# EFM32G222F128 register map
File version: 5.2.1
Registers are 32-bit, read-write, reset 0x0 unless marked. A register's access mark holds for its fields unless they carry their own. Offsets are from the block's base; [hi:lo] are bit positions; {n}, {i} and the like mark numbered series.

## ACMP0
Base 0x40001000
Same registers: ACMP1 0x40001400
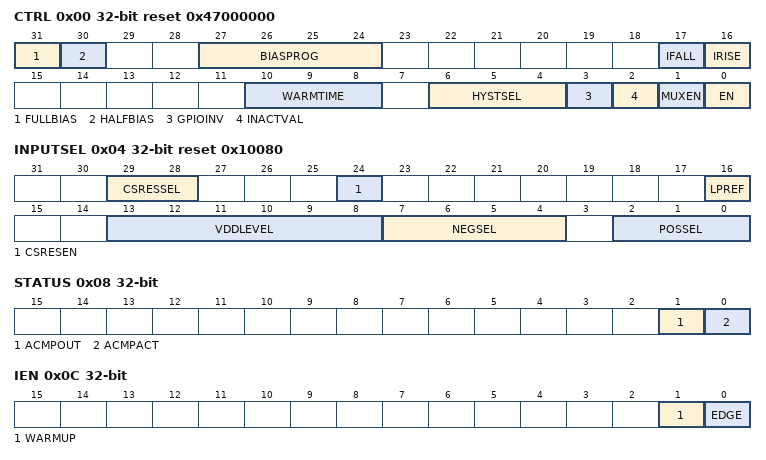
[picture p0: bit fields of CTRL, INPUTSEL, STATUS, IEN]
0x00 CTRL reset 0x47000000 — Control Register
  [31] FULLBIAS — Full Bias Current
  [30] HALFBIAS — Half Bias Current
  [27:24] BIASPROG — Bias Configuration
  [17] IFALL — Falling Edge Interrupt Sense
  [16] IRISE — Rising Edge Interrupt Sense
  [10:8] WARMTIME — Warm-up Time
    0=4CYCLES (4 HFPERCLK cycles.); 1=8CYCLES (8 HFPERCLK cycles.); 2=16CYCLES (16 HFPERCLK cycles.); 3=32CYCLES (32 HFPERCLK cycles.); 4=64CYCLES (64 HFPERCLK cycles.); 5=128CYCLES (128 HFPERCLK cycles.); 6=256CYCLES (256 HFPERCLK cycles.); 7=512CYCLES (512 HFPERCLK cycles.)
  [6:4] HYSTSEL — Hysteresis Select
    0=HYST0 (No hysteresis.); 1=HYST1 (~15 mV hysteresis.); 2=HYST2 (~22 mV hysteresis.); 3=HYST3 (~29 mV hysteresis.); 4=HYST4 (~36 mV hysteresis.); 5=HYST5 (~43 mV hysteresis.); 6=HYST6 (~50 mV hysteresis.); 7=HYST7 (~57 mV hysteresis.)
  [3] GPIOINV — Comparator GPIO Output Invert
  [2] INACTVAL — Inactive Value
  [1] MUXEN — Input Mux Enable
  [0] EN — Analog Comparator Enable
0x04 INPUTSEL reset 0x10080 — Input Selection Register
  [29:28] CSRESSEL — Capacitive Sense Mode Internal Resistor Select
    {v}=RES{v} (Internal capacitive sense resistor value {v}.) (v=0..3)
  [24] CSRESEN — Capacitive Sense Mode Internal Resistor Enable
  [16] LPREF — Low Power Reference Mode
  [13:8] VDDLEVEL — VDD Reference Level
  [7:4] NEGSEL — Negative Input Select
    {v}=CH{v} (Channel {v} as negative input.) (v=0..7); 8=1V25 (1.25 V as negative input.); 9=2V5 (2.5 V as negative input.); 10=VDD (Scaled VDD as negative input.); 11=CAPSENSE (Capacitive sense mode.)
  [2:0] POSSEL — Positive Input Select
    {v}=CH{v} (Channel {v} as positive input.) (v=0..7)
0x08 STATUS ro
  [1] ACMPOUT — Analog Comparator Output
  [0] ACMPACT — Analog Comparator Active
0x0C IEN — Interrupt Enable Register
  [1] WARMUP — Warm-up Interrupt Enable
  [0] EDGE — Edge Trigger Interrupt Enable
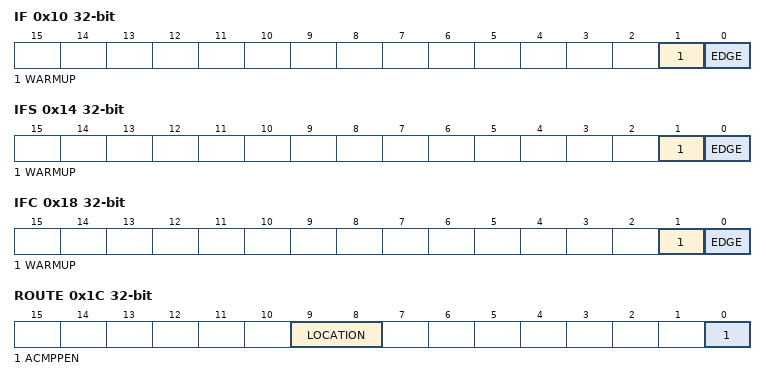
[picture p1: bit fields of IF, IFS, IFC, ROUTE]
0x10 IF ro — Interrupt Flag Register
  [1] WARMUP — Warm-up Interrupt Flag
  [0] EDGE — Edge Triggered Interrupt Flag
0x14 IFS wo — Interrupt Flag Set Register
  [1] WARMUP — Warm-up Interrupt Flag Set
  [0] EDGE — Edge Triggered Interrupt Flag Set
0x18 IFC wo — Interrupt Flag Clear Register
  [1] WARMUP — Warm-up Interrupt Flag Clear
  [0] EDGE — Edge Triggered Interrupt Flag Clear
0x1C ROUTE — I/O Routing Register
  [9:8] LOCATION — I/O Location
    0=LOC0 (Location 0); 1=LOC1 (Location 1)
  [0] ACMPPEN — ACMP Output Pin Enable

## PRS
Base 0x400CC000
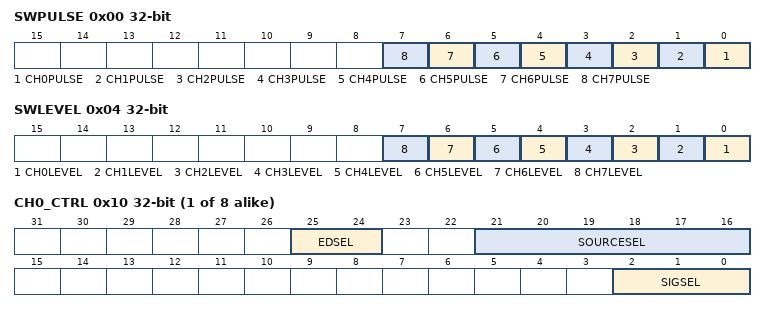
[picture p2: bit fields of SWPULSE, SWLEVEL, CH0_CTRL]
0x00 SWPULSE wo — Software Pulse Register
  [n] CH{n}PULSE (n=0..7) — Channel {n} Pulse Generation
0x04 SWLEVEL — Software Level Register
  [n] CH{n}LEVEL (n=0..7) — Channel {n} Software Level
{0x10+4i} CH{i}_CTRL (i=0..7) — Channel Control Register
  [25:24] EDSEL — Edge Detect Select
    0=OFF (Signal is left as it is); 1=POSEDGE (A one HFPERCLK cycle pulse is generated for every positive edge of the incoming signal); 2=NEGEDGE (A one HFPERCLK clock cycle pulse is generated for every negative edge of the incoming signal); 3=BOTHEDGES (A one HFPERCLK clock cycle pulse is generated for every edge of the incoming signal)
  [21:16] SOURCESEL — Source Select
    0=NONE (No source selected); 1=VCMP (Voltage Comparator); 2=ACMP0 (Analog Comparator 0); 3=ACMP1 (Analog Comparator 1); 6=DAC0 (Digital to Analog Converter 0); 8=ADC0 (Analog to Digital Converter 0); 16=USART0 (Universal Synchronous/Asynchronous Receiver/Transmitter 0); 17=USART1 (Universal Synchronous/Asynchronous Receiver/Transmitter 1); 28=TIMER0; 29=TIMER1; 30=TIMER2; 40=RTC (Real-Time Counter); 48=GPIOL (General purpose Input/Output); 49=GPIOH (General purpose Input/Output)
  [2:0] SIGSEL — Signal Select

## DAC0
Base 0x40004000
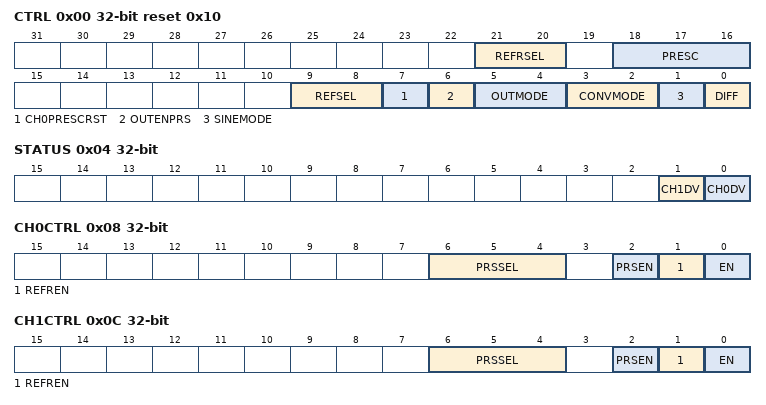
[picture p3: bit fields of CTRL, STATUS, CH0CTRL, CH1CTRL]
0x00 CTRL reset 0x10 — Control Register
  [21:20] REFRSEL — Refresh Interval Select
    0=8CYCLES (All channels with enabled refresh are refreshed every 8 prescaled cycles); 1=16CYCLES (All channels with enabled refresh are refreshed every 16 prescaled cycles); 2=32CYCLES (All channels with enabled refresh are refreshed every 32 prescaled cycles); 3=64CYCLES (All channels with enabled refresh are refreshed every 64 prescaled cycles)
  [18:16] PRESC — Prescaler Setting
    0=NODIVISION
  [9:8] REFSEL — Reference Selection
    0=1V25 (Internal 1.25 V bandgap reference); 1=2V5 (Internal 2.5 V bandgap reference); 2=VDD (VDD reference)
  [7] CH0PRESCRST — Channel 0 Start Reset Prescaler
  [6] OUTENPRS — PRS Controlled Output Enable
  [5:4] OUTMODE — Output Mode
    0=DISABLE (DAC output to pin and ADC disabled); 1=PIN (DAC output to pin enabled. DAC output to ADC disabled); 2=ADC (DAC output to pin disabled. DAC output to ADC enabled); 3=PINADC (DAC output to pin and ADC enabled)
  [3:2] CONVMODE — Conversion Mode
    0=CONTINUOUS (DAC is set in continuous mode); 1=SAMPLEHOLD (DAC is set in sample/hold mode); 2=SAMPLEOFF (DAC is set in sample/shut off mode)
  [1] SINEMODE
  [0] DIFF — Differential Mode
0x04 STATUS ro
  [1] CH1DV — Channel 1 Data Valid
  [0] CH0DV — Channel 0 Data Valid
0x08 CH0CTRL — Channel 0 Control Register
  [6:4] PRSSEL — Channel 0 PRS Trigger Select
    {v}=PRSCH{v} (PRS ch {v} triggers channel 0 conversion.) (v=0..7)
  [2] PRSEN — Channel 0 PRS Trigger Enable
  [1] REFREN — Channel 0 Automatic Refresh Enable
  [0] EN — Channel 0 Enable
0x0C CH1CTRL — Channel 1 Control Register
  [6:4] PRSSEL — Channel 1 PRS Trigger Select
    {v}=PRSCH{v} (PRS ch {v} triggers channel 1 conversion.) (v=0..7)
  [2] PRSEN — Channel 1 PRS Trigger Enable
  [1] REFREN — Channel 1 Automatic Refresh Enable
  [0] EN — Channel 1 Enable
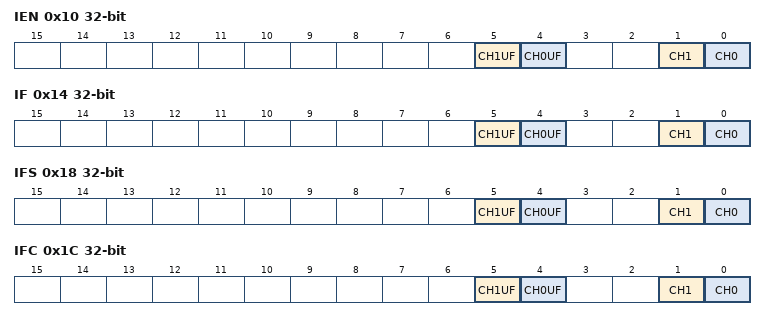
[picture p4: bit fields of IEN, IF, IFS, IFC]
0x10 IEN — Interrupt Enable Register
  [5] CH1UF — Channel 1 Conversion Data Underflow Interrupt Enable
  [4] CH0UF — Channel 0 Conversion Data Underflow Interrupt Enable
  [1] CH1 — Channel 1 Conversion Complete Interrupt Enable
  [0] CH0 — Channel 0 Conversion Complete Interrupt Enable
0x14 IF ro — Interrupt Flag Register
  [5] CH1UF — Channel 1 Data Underflow Interrupt Flag
  [4] CH0UF — Channel 0 Data Underflow Interrupt Flag
  [1] CH1 — Channel 1 Conversion Complete Interrupt Flag
  [0] CH0 — Channel 0 Conversion Complete Interrupt Flag
0x18 IFS wo — Interrupt Flag Set Register
  [5] CH1UF — Channel 1 Data Underflow Interrupt Flag Set
  [4] CH0UF — Channel 0 Data Underflow Interrupt Flag Set
  [1] CH1 — Channel 1 Conversion Complete Interrupt Flag Set
  [0] CH0 — Channel 0 Conversion Complete Interrupt Flag Set
0x1C IFC wo — Interrupt Flag Clear Register
  [5] CH1UF — Channel 1 Data Underflow Interrupt Flag Clear
  [4] CH0UF — Channel 0 Data Underflow Interrupt Flag Clear
  [1] CH1 — Channel 1 Conversion Complete Interrupt Flag Clear
  [0] CH0 — Channel 0 Conversion Complete Interrupt Flag Clear
0x20 CH0DATA — Channel 0 Data Register
  [11:0] DATA — Channel 0 Data
0x24 CH1DATA — Channel 1 Data Register
  [11:0] DATA — Channel 1 Data
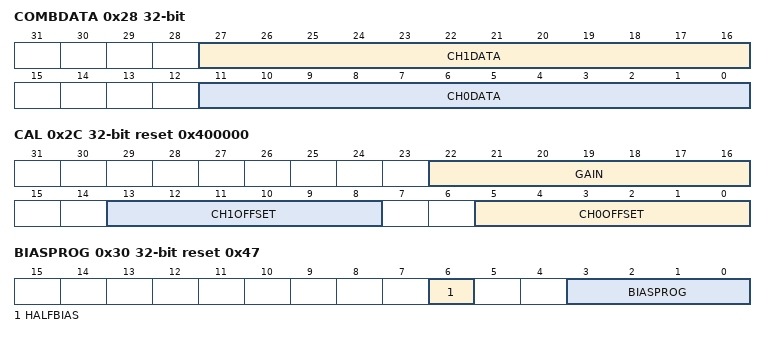
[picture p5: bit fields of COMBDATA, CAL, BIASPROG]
0x28 COMBDATA wo — Combined Data Register
  [27:16] CH1DATA — Channel 1 Data
  [11:0] CH0DATA — Channel 0 Data
0x2C CAL reset 0x400000 — Calibration Register
  [22:16] GAIN — Gain Calibration Value
  [13:8] CH1OFFSET — Channel 1 Offset Calibration Value
  [5:0] CH0OFFSET — Channel 0 Offset Calibration Value
0x30 BIASPROG reset 0x47 — Bias Programming Register
  [6] HALFBIAS — Half Bias Current
  [3:0] BIASPROG — Bias Programming Value

## VCMP
Base 0x40000000
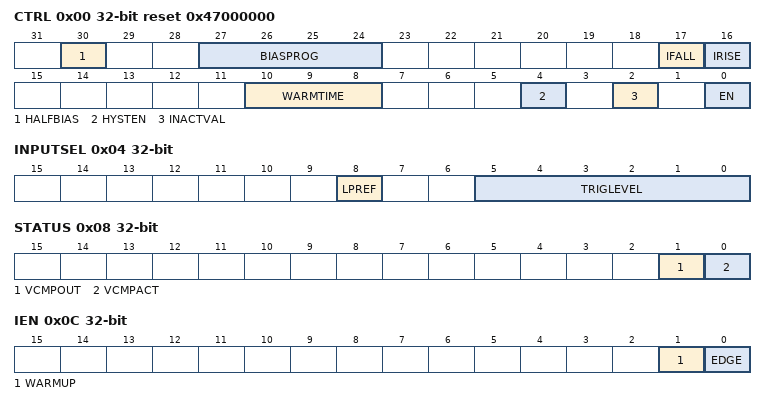
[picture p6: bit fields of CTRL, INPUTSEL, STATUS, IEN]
0x00 CTRL reset 0x47000000 — Control Register
  [30] HALFBIAS — Half Bias Current
  [27:24] BIASPROG — VCMP Bias Programming Value
  [17] IFALL — Falling Edge Interrupt Sense
  [16] IRISE — Rising Edge Interrupt Sense
  [10:8] WARMTIME — Warm-Up Time
    0=4CYCLES (4 HFPERCLK cycles); 1=8CYCLES (8 HFPERCLK cycles); 2=16CYCLES (16 HFPERCLK cycles); 3=32CYCLES (32 HFPERCLK cycles); 4=64CYCLES (64 HFPERCLK cycles); 5=128CYCLES (128 HFPERCLK cycles); 6=256CYCLES (256 HFPERCLK cycles); 7=512CYCLES (512 HFPERCLK cycles)
  [4] HYSTEN — Hysteresis Enable
  [2] INACTVAL — Inactive Value
  [0] EN — Voltage Supply Comparator Enable
0x04 INPUTSEL — Input Selection Register
  [8] LPREF — Low Power Reference
  [5:0] TRIGLEVEL — Trigger Level
0x08 STATUS ro
  [1] VCMPOUT — Voltage Supply Comparator Output
  [0] VCMPACT — Voltage Supply Comparator Active
0x0C IEN — Interrupt Enable Register
  [1] WARMUP — Warm-up Interrupt Enable
  [0] EDGE — Edge Trigger Interrupt Enable
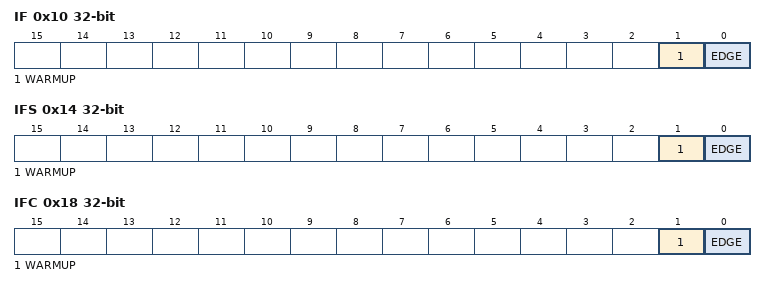
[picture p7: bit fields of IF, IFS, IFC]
0x10 IF ro — Interrupt Flag Register
  [1] WARMUP — Warm-up Interrupt Flag
  [0] EDGE — Edge Triggered Interrupt Flag
0x14 IFS wo — Interrupt Flag Set Register
  [1] WARMUP — Warm-up Interrupt Flag Set
  [0] EDGE — Edge Triggered Interrupt Flag Set
0x18 IFC wo — Interrupt Flag Clear Register
  [1] WARMUP — Warm-up Interrupt Flag Clear
  [0] EDGE — Edge Triggered Interrupt Flag Clear

## WDOG
Base 0x40088000
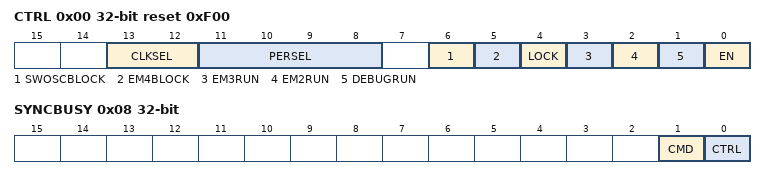
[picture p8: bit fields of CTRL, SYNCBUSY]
0x00 CTRL reset 0xF00 — Control Register
  [13:12] CLKSEL — Watchdog Clock Select
    0=ULFRCO; 1=LFRCO; 2=LFXO
  [11:8] PERSEL — Watchdog Timeout Period Select
  [6] SWOSCBLOCK — Software Oscillator Disable Block
  [5] EM4BLOCK — Energy Mode 4 Block
  [4] LOCK — Configuration lock
  [3] EM3RUN — Energy Mode 3 Run Enable
  [2] EM2RUN — Energy Mode 2 Run Enable
  [1] DEBUGRUN — Debug Mode Run Enable
  [0] EN — Watchdog Timer Enable
0x04 CMD wo — Command Register
  [0] CLEAR — Watchdog Timer Clear
0x08 SYNCBUSY ro — Synchronization Busy Register
  [1] CMD — CMD Register Busy
  [0] CTRL — CTRL Register Busy
